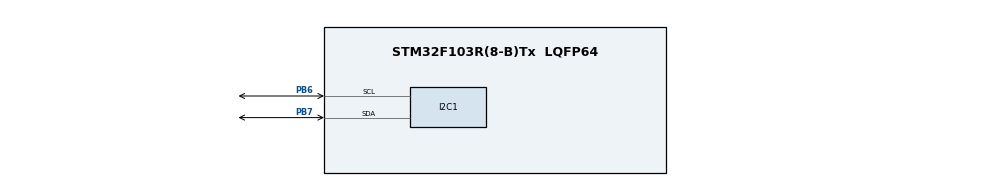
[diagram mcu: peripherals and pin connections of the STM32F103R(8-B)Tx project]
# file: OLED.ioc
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Mcu.Family=STM32F1
Mcu.Name=STM32F103R(8-B)Tx
Mcu.Package=LQFP64
NVIC.PriorityGroup=NVIC_PRIORITYGROUP_4
PB6.Mode=I2C
PB6.Signal=I2C1_SCL
PB7.Mode=I2C
PB7.Signal=I2C1_SDA
ProjectManager.HeapSize=0x200
ProjectManager.StackSize=0x400
ProjectManager.TargetToolchain=MDK-ARM V5
RCC.APB1Freq_Value=8000000
RCC.APB2Freq_Value=8000000
VP_SYS_VS_ND.Mode=No_Debug
board=custom

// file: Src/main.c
/* USER CODE BEGIN Header */
/**
  ******************************************************************************
  * @file           : main.c
  * @brief          : Main program body
  ******************************************************************************
  * @attention
  *
  * <h2><center>&copy; Copyright (c) 2020 STMicroelectronics.
  * All rights reserved.</center></h2>
  *
  * This software component is licensed by ST under BSD 3-Clause license,
  * the "License"; You may not use this file except in compliance with the
  * License. You may obtain a copy of the License at:
  *                        opensource.org/licenses/BSD-3-Clause
  *
  ******************************************************************************
  */
/* USER CODE END Header */

#include "main.h"
#include "i2c.h"
#include "gpio.h"
#include "oled.h"
#include "bmp.h"

void SystemClock_Config(void);

int main(void)
{
  /* USER CODE BEGIN 1 */
	extern I2C_HandleTypeDef hi2c1;
  /* USER CODE END 1 */

  /* MCU Configuration--------------------------------------------------------*/

  /* Reset of all peripherals, Initializes the Flash interface and the Systick. */
  HAL_Init();

  /* Configure the system clock */
  SystemClock_Config();

  /* Initialize all configured peripherals */
  MX_GPIO_Init();
  MX_I2C1_Init();
  /* USER CODE BEGIN 2 */
	HAL_I2C_MspInit(&hi2c1);//手动添加
	OLED_Init ();
	OLED_Clear();
  /* USER CODE END 2 */

  /* Infinite loop */
  while (1)
  {
		//OLED_Clear();
//
//		OLED_ShowCHinese(108,0,6);//技
//		OLED_ShowString(72,0,"@EAGLE",16);
//		OLED_ShowString(6,3,"0.96' OLED TEST",16);
//		OLED_ShowString(8,2,"ZHONGJINGYUAN",16);
//	 	OLED_ShowString(20,4,"2014/05/01",16);
//		OLED_ShowString(0,6,"ASCII:",16);
//		OLED_ShowString(63,6,"CODE:",16);
//				OLED_ShowChar(48,0,'C',16);//前两个是坐标。第三个是输入的是ASIIC码加上空格的一个整型数，第四个是字体大小，有8*16和6*16的规格
		OLED_DrawBMP(0,0,127,4,BMP1);
		OLED_ShowCHinese(0,6,0);  //我
		OLED_ShowCHinese(20,6,1);//爱
		OLED_ShowCHinese(40,6,2);//学
		OLED_ShowCHinese(60,6,3);//习
//		OLED_ShowCHinese(72,6,4);//子
//		OLED_ShowCHinese(90,6,5);//科
//		OLED_ShowChar(48,6,48,16);//前两个是坐标。第三个是输入的是ASIIC码加上空格的一个整型数，第四个是字体大小，有8*16和6*16的规格
//
//		if(t>'~')t=' ';
//		OLED_ShowNum(103,6,t,3,16);//显示ASCII字符的码值
//			delay_ms(8000);
		HAL_Delay(10000);
  }
}

void SystemClock_Config(void)
{
  RCC_OscInitTypeDef RCC_OscInitStruct = {0};
  RCC_ClkInitTypeDef RCC_ClkInitStruct = {0};

  /** Initializes the CPU, AHB and APB busses clocks
  */
  RCC_OscInitStruct.OscillatorType = RCC_OSCILLATORTYPE_HSI;
  RCC_OscInitStruct.HSIState = RCC_HSI_ON;
  RCC_OscInitStruct.HSICalibrationValue = RCC_HSICALIBRATION_DEFAULT;
  RCC_OscInitStruct.PLL.PLLState = RCC_PLL_NONE;
  if (HAL_RCC_OscConfig(&RCC_OscInitStruct) != HAL_OK)
  {
    Error_Handler();
  }
  /** Initializes the CPU, AHB and APB busses clocks
  */
  RCC_ClkInitStruct.ClockType = RCC_CLOCKTYPE_HCLK|RCC_CLOCKTYPE_SYSCLK
                              |RCC_CLOCKTYPE_PCLK1|RCC_CLOCKTYPE_PCLK2;
  RCC_ClkInitStruct.SYSCLKSource = RCC_SYSCLKSOURCE_HSI;
  RCC_ClkInitStruct.AHBCLKDivider = RCC_SYSCLK_DIV1;
  RCC_ClkInitStruct.APB1CLKDivider = RCC_HCLK_DIV1;
  RCC_ClkInitStruct.APB2CLKDivider = RCC_HCLK_DIV1;

  if (HAL_RCC_ClockConfig(&RCC_ClkInitStruct, FLASH_LATENCY_0) != HAL_OK)
  {
    Error_Handler();
  }
}

void Error_Handler(void)
{
}

/************************ (C) COPYRIGHT STMicroelectronics *****END OF FILE****/
